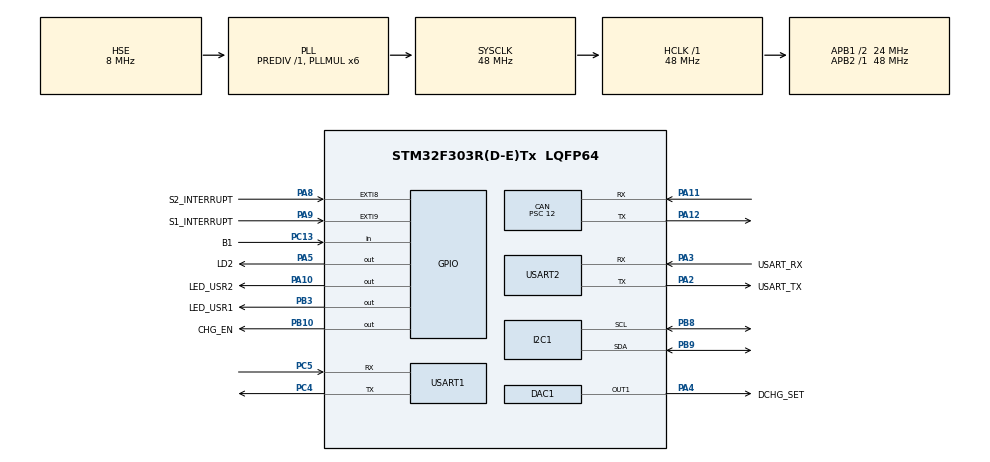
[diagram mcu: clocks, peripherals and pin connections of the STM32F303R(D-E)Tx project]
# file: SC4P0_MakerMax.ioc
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CAN.BS1=CAN_BS1_13TQ
CAN.BS2=CAN_BS2_2TQ
CAN.CalculateTimeQuantum=500.0
CAN.Mode=CAN_MODE_NORMAL
CAN.NART=ENABLE
CAN.Prescaler=12
FREERTOS.MEMORY_ALLOCATION=1
FREERTOS.Tasks01=defaultTask,0,1024,StartDefaultTask,Default,NULL,Static,defaultTaskBuffer,defaultTaskControlBlock
FREERTOS.configMAX_PRIORITIES=7
FREERTOS.configMINIMAL_STACK_SIZE=1024
FREERTOS.configTOTAL_HEAP_SIZE=15360
FREERTOS.configUSE_PREEMPTION=0
I2C1.AddressingMode=I2C_ADDRESSINGMODE_7BIT
Mcu.Family=STM32F3
Mcu.Name=STM32F303R(D-E)Tx
Mcu.Package=LQFP64
NVIC.EXTI9_5_IRQn=true\:5\:0\:false\:false\:true\:true\:true\:true
NVIC.PriorityGroup=NVIC_PRIORITYGROUP_4
NVIC.TIM1_TRG_COM_TIM17_IRQn=true\:5\:0\:false\:false\:true\:true\:true\:true
NVIC.TIM1_UP_TIM16_IRQn=true\:5\:0\:false\:false\:true\:true\:true\:true
NVIC.TIM6_DAC_IRQn=true\:5\:0\:false\:false\:true\:true\:true\:true
NVIC.TIM7_IRQn=true\:5\:0\:false\:false\:true\:true\:true\:true
NVIC.USART1_IRQn=true\:5\:0\:false\:false\:true\:true\:true\:true
NVIC.USB_LP_CAN_RX0_IRQn=true\:5\:0\:false\:false\:true\:true\:true\:true
PA10.GPIO_Label=LED_USR2
PA10.GPIO_ModeDefaultOutputPP=GPIO_MODE_OUTPUT_PP
PA10.GPIO_PuPd=GPIO_NOPULL
PA10.GPIO_Speed=GPIO_SPEED_FREQ_LOW
PA10.PinState=GPIO_PIN_RESET
PA10.Signal=GPIO_Output
PA11.Mode=Master
PA11.Signal=CAN_RX
PA12.Mode=Master
PA12.Signal=CAN_TX
PA13.GPIO_Label=TMS
PA13.Mode=Serial_Wire
PA13.Signal=SYS_JTMS-SWDIO
PA14.GPIO_Label=TCK
PA14.Mode=Serial_Wire
PA14.Signal=SYS_JTCK-SWCLK
PA2.GPIO_Label=USART_TX
PA2.GPIO_Mode=GPIO_MODE_AF_PP
PA2.GPIO_ModeDefaultPP=GPIO_MODE_AF_PP
PA2.GPIO_PuPd=GPIO_NOPULL
PA2.GPIO_Speed=GPIO_SPEED_FREQ_HIGH
PA2.Mode=Asynchronous
PA2.Signal=USART2_TX
PA3.GPIO_Label=USART_RX
PA3.GPIO_Mode=GPIO_MODE_AF_PP
PA3.GPIO_ModeDefaultPP=GPIO_MODE_AF_PP
PA3.GPIO_PuPd=GPIO_NOPULL
PA3.GPIO_Speed=GPIO_SPEED_FREQ_HIGH
PA3.Mode=Asynchronous
PA3.Signal=USART2_RX
PA4.GPIO_Label=DCHG_SET
PA4.GPIO_Mode=GPIO_MODE_ANALOG
PA4.GPIO_PuPd=GPIO_NOPULL
PA4.Signal=COMP_DAC11_group
PA5.GPIO_Label=LD2
PA5.GPIO_Mode=GPIO_MODE_OUTPUT_PP
PA5.GPIO_ModeDefaultOutputPP=GPIO_MODE_OUTPUT_PP
PA5.GPIO_PuPd=GPIO_NOPULL
PA5.GPIO_Speed=GPIO_SPEED_FREQ_LOW
PA5.PinState=GPIO_PIN_RESET
PA5.Signal=GPIO_Output
PA8.GPIO_Label=S2_INTERRUPT
PA8.GPIO_ModeDefaultEXTI=GPIO_MODE_IT_FALLING
PA8.GPIO_PuPd=GPIO_PULLUP
PA8.Signal=GPXTI8
PA9.GPIO_Label=S1_INTERRUPT
PA9.GPIO_ModeDefaultEXTI=GPIO_MODE_IT_FALLING
PA9.GPIO_PuPd=GPIO_PULLUP
PA9.Signal=GPXTI9
PB10.GPIO_Label=CHG_EN
PB10.GPIO_ModeDefaultOutputPP=GPIO_MODE_OUTPUT_PP
PB10.GPIO_PuPd=GPIO_NOPULL
PB10.GPIO_Speed=GPIO_SPEED_FREQ_LOW
PB10.PinState=GPIO_PIN_RESET
PB10.Signal=GPIO_Output
PB3.GPIO_Label=LED_USR1
PB3.GPIO_ModeDefaultOutputPP=GPIO_MODE_OUTPUT_PP
PB3.GPIO_PuPd=GPIO_NOPULL
PB3.GPIO_Speed=GPIO_SPEED_FREQ_LOW
PB3.PinState=GPIO_PIN_RESET
PB3.Signal=GPIO_Output
PB8.GPIO_Mode=GPIO_MODE_AF_OD
PB8.GPIO_PuPdOD=GPIO_NOPULL
PB8.GPIO_Speed=GPIO_SPEED_FREQ_HIGH
PB8.Mode=I2C
PB8.Signal=I2C1_SCL
PB9.GPIO_FM7=__NULL
PB9.GPIO_Mode=GPIO_MODE_AF_OD
PB9.GPIO_PuPdOD=GPIO_NOPULL
PB9.GPIO_Speed=GPIO_SPEED_FREQ_HIGH
PB9.Mode=I2C
PB9.Signal=I2C1_SDA
PC13.GPIO_Label=B1
PC13.Signal=GPIO_Input
PC14-OSC32_IN.Signal=RCC_OSC32_IN
PC15-OSC32_OUT.Signal=RCC_OSC32_OUT
PC4.Mode=Asynchronous
PC4.Signal=USART1_TX
PC5.Mode=Asynchronous
PC5.Signal=USART1_RX
PF0-OSC_IN.Mode=HSE-External-Oscillator
PF0-OSC_IN.Signal=RCC_OSC_IN
PF1-OSC_OUT.Mode=HSE-External-Oscillator
PF1-OSC_OUT.Signal=RCC_OSC_OUT
ProjectManager.HeapSize=0x200
ProjectManager.StackSize=0x400
ProjectManager.TargetToolchain=TrueSTUDIO
RCC.AHBFreq_Value=48000000
RCC.APB1CLKDivider=RCC_HCLK_DIV2
RCC.APB1Freq_Value=24000000
RCC.APB1TimFreq_Value=48000000
RCC.APB2Freq_Value=48000000
RCC.APB2TimFreq_Value=48000000
RCC.CortexFreq_Value=48000000
RCC.HCLKFreq_Value=48000000
RCC.HSE_VALUE=8000000
RCC.HSI_VALUE=8000000
RCC.LSE_VALUE=32768
RCC.PLLM=8
RCC.PLLMUL=RCC_PLL_MUL6
RCC.PLLN=336
RCC.PLLP=RCC_PLLP_DIV4
RCC.PLLQ=7
RCC.PLLSourceVirtual=RCC_PLLSOURCE_HSE
RCC.RCC_PLLsource_Clock_Source_FROM_HSE=RCC_HSE_PREDIV_DIV2
RCC.SYSCLKFreq_VALUE=48000000
RCC.SYSCLKSourceVirtual=RCC_SYSCLKSOURCE_PLLCLK
RCC.USBFreq_Value=48000000
SH.COMP_DAC11_group.0=DAC1_OUT1,DAC_OUT1
TIM16.Period=2500
TIM16.Prescaler=36000
TIM17.Period=2500
TIM17.Prescaler=36000
TIM6.Period=2500
TIM6.Prescaler=36000
TIM7.Period=0
TIM7.Prescaler=0
USART1.VirtualMode-Asynchronous=VM_ASYNC
USART2.VirtualMode-Asynchronous=VM_ASYNC
VP_FREERTOS_VS_CMSIS_V1.Mode=CMSIS_V1
VP_TIM16_VS_ClockSourceINT.Mode=Enable_Timer
VP_TIM17_VS_ClockSourceINT.Mode=Enable_Timer
VP_TIM6_VS_ClockSourceINT.Mode=Enable_Timer
VP_TIM7_VS_ClockSourceINT.Mode=Enable_Timer
board=NUCLEO-F303RE

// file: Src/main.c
/* USER CODE BEGIN Header */
/**
  ******************************************************************************
  * @file           : main.c
  * @brief          : Main program body
  ******************************************************************************
  ** This notice applies to any and all portions of this file
  * that are not between comment pairs USER CODE BEGIN and
  * USER CODE END. Other portions of this file, whether
  * inserted by the user or by software development tools
  * are owned by their respective copyright owners.
  *
  * COPYRIGHT(c) 2019 STMicroelectronics and MakerMax Inc.
  *
  * Redistribution and use in source and binary forms, with or without modification,
  * are permitted provided that the following conditions are met:
  *   1. Redistributions of source code must retain the above copyright notice,
  *      this list of conditions and the following disclaimer.
  *   2. Redistributions in binary form must reproduce the above copyright notice,
  *      this list of conditions and the following disclaimer in the documentation
  *      and/or other materials provided with the distribution.
  *   3. Neither the name of STMicroelectronics nor the names of its contributors
  *      may be used to endorse or promote products derived from this software
  *      without specific prior written permission.
  *
  * THIS SOFTWARE IS PROVIDED BY THE COPYRIGHT HOLDERS AND CONTRIBUTORS "AS IS"
  * AND ANY EXPRESS OR IMPLIED WARRANTIES, INCLUDING, BUT NOT LIMITED TO, THE
  * IMPLIED WARRANTIES OF MERCHANTABILITY AND FITNESS FOR A PARTICULAR PURPOSE ARE
  * DISCLAIMED. IN NO EVENT SHALL THE COPYRIGHT HOLDER OR CONTRIBUTORS BE LIABLE
  * FOR ANY DIRECT, INDIRECT, INCIDENTAL, SPECIAL, EXEMPLARY, OR CONSEQUENTIAL
  * DAMAGES (INCLUDING, BUT NOT LIMITED TO, PROCUREMENT OF SUBSTITUTE GOODS OR
  * SERVICES; LOSS OF USE, DATA, OR PROFITS; OR BUSINESS INTERRUPTION) HOWEVER
  * CAUSED AND ON ANY THEORY OF LIABILITY, WHETHER IN CONTRACT, STRICT LIABILITY,
  * OR TORT (INCLUDING NEGLIGENCE OR OTHERWISE) ARISING IN ANY WAY OUT OF THE USE
  * OF THIS SOFTWARE, EVEN IF ADVISED OF THE POSSIBILITY OF SUCH DAMAGE.
  *
  ******************************************************************************
  */
/* USER CODE END Header */

#include "main.h"
#include "cmsis_os.h"

/* USER CODE BEGIN Includes */
//#include <stdarg.h>
#include <stdio.h>
#include <string.h>
#include "bms.h"
#include "can.h"
#include "modbus_helper.h"

/* USER CODE END Includes */

CAN_HandleTypeDef hcan;

DAC_HandleTypeDef hdac1;

I2C_HandleTypeDef hi2c1;

TIM_HandleTypeDef htim6;
TIM_HandleTypeDef htim7;
TIM_HandleTypeDef htim16;
TIM_HandleTypeDef htim17;

UART_HandleTypeDef huart1;
UART_HandleTypeDef huart2;

osThreadId defaultTaskHandle;
uint32_t defaultTaskBuffer[ 1024 ];
osStaticThreadDef_t defaultTaskControlBlock;

void SystemClock_Config(void);
static void MX_GPIO_Init(void);
static void MX_DAC1_Init(void);
static void MX_I2C1_Init(void);
static void MX_TIM6_Init(void);
static void MX_USART2_UART_Init(void);
static void MX_TIM7_Init(void);
static void MX_TIM16_Init(void);
static void MX_TIM17_Init(void);
static void MX_USART1_UART_Init(void);
static void MX_CAN_Init(void);
void StartDefaultTask(void const * argument);

int main(void)
{

  /* MCU Configuration--------------------------------------------------------*/

  /* Reset of all peripherals, Initializes the Flash interface and the Systick. */
  HAL_Init();

  /* Configure the system clock */
  SystemClock_Config();

  /* Initialize all configured peripherals */
  MX_GPIO_Init();
  MX_DAC1_Init();
  MX_I2C1_Init();
  MX_TIM6_Init();
  MX_USART2_UART_Init();
  MX_TIM7_Init();
  MX_TIM16_Init();
  MX_TIM17_Init();
  MX_USART1_UART_Init();
  MX_CAN_Init();
  /* USER CODE BEGIN 2 */

  /*
   * Initialize TIM7 to run safety loop
   */

  //HAL_TIM_Base_Start_IT(&htim7);
  HAL_TIM_Base_Start_IT(&htim16);

  /*
   * Initialize BMS
   */
  InitBMS();

  /*
   * Initialize CAN
   */
  InitCAN();

  /*
   * Initialize modbus
   */
  enable_modbusrtu();

  /* USER CODE END 2 */

  /* Create the thread(s) */
  /* definition and creation of defaultTask */
  //osThreadStaticDef(defaultTask, StartDefaultTask, osPriorityNormal, 0, 1024, defaultTaskBuffer, &defaultTaskControlBlock);
  //defaultTaskHandle = osThreadCreate(osThread(defaultTask), NULL);

  /* USER CODE BEGIN RTOS_THREADS */
  /* add threads, ... */

  bms_task_init();
  can_task_init();
  modbus_task_init();

  /* USER CODE END RTOS_THREADS */

  /* Start scheduler */
  osKernelStart();

  /* We should never get here as control is now taken by the scheduler */

  /* Infinite loop */
  while (1)
  {

  }
}

void SystemClock_Config(void)
{
  RCC_OscInitTypeDef RCC_OscInitStruct = {0};
  RCC_ClkInitTypeDef RCC_ClkInitStruct = {0};
  RCC_PeriphCLKInitTypeDef PeriphClkInit = {0};

  /** Initializes the CPU, AHB and APB busses clocks
  */
  RCC_OscInitStruct.OscillatorType = RCC_OSCILLATORTYPE_HSI|RCC_OSCILLATORTYPE_HSE;
  RCC_OscInitStruct.HSEState = RCC_HSE_ON;
  RCC_OscInitStruct.HSIState = RCC_HSI_ON;
  RCC_OscInitStruct.HSICalibrationValue = RCC_HSICALIBRATION_DEFAULT;
  RCC_OscInitStruct.PLL.PLLState = RCC_PLL_ON;
  RCC_OscInitStruct.PLL.PLLSource = RCC_PLLSOURCE_HSE;
  RCC_OscInitStruct.PLL.PLLMUL = RCC_PLL_MUL6;
  RCC_OscInitStruct.PLL.PREDIV = RCC_PREDIV_DIV1;
  if (HAL_RCC_OscConfig(&RCC_OscInitStruct) != HAL_OK)
  {
    Error_Handler();
  }
  /** Initializes the CPU, AHB and APB busses clocks
  */
  RCC_ClkInitStruct.ClockType = RCC_CLOCKTYPE_HCLK|RCC_CLOCKTYPE_SYSCLK
                              |RCC_CLOCKTYPE_PCLK1|RCC_CLOCKTYPE_PCLK2;
  RCC_ClkInitStruct.SYSCLKSource = RCC_SYSCLKSOURCE_PLLCLK;
  RCC_ClkInitStruct.AHBCLKDivider = RCC_SYSCLK_DIV1;
  RCC_ClkInitStruct.APB1CLKDivider = RCC_HCLK_DIV2;
  RCC_ClkInitStruct.APB2CLKDivider = RCC_HCLK_DIV1;

  if (HAL_RCC_ClockConfig(&RCC_ClkInitStruct, FLASH_LATENCY_1) != HAL_OK)
  {
    Error_Handler();
  }
  PeriphClkInit.PeriphClockSelection = RCC_PERIPHCLK_USART1|RCC_PERIPHCLK_USART2
                              |RCC_PERIPHCLK_I2C1|RCC_PERIPHCLK_TIM16
                              |RCC_PERIPHCLK_TIM17;
  PeriphClkInit.Usart1ClockSelection = RCC_USART1CLKSOURCE_PCLK2;
  PeriphClkInit.Usart2ClockSelection = RCC_USART2CLKSOURCE_PCLK1;
  PeriphClkInit.I2c1ClockSelection = RCC_I2C1CLKSOURCE_HSI;
  PeriphClkInit.Tim16ClockSelection = RCC_TIM16CLK_HCLK;
  PeriphClkInit.Tim17ClockSelection = RCC_TIM17CLK_HCLK;
  if (HAL_RCCEx_PeriphCLKConfig(&PeriphClkInit) != HAL_OK)
  {
    Error_Handler();
  }
}

static void MX_CAN_Init(void)
{

  hcan.Instance = CAN;
  hcan.Init.Prescaler = 12;
  hcan.Init.Mode = CAN_MODE_NORMAL;
  hcan.Init.SyncJumpWidth = CAN_SJW_1TQ;
  hcan.Init.TimeSeg1 = CAN_BS1_13TQ;
  hcan.Init.TimeSeg2 = CAN_BS2_2TQ;
  hcan.Init.TimeTriggeredMode = DISABLE;
  hcan.Init.AutoBusOff = DISABLE;
  hcan.Init.AutoWakeUp = DISABLE;
  hcan.Init.AutoRetransmission = ENABLE;
  hcan.Init.ReceiveFifoLocked = DISABLE;
  hcan.Init.TransmitFifoPriority = DISABLE;
  if (HAL_CAN_Init(&hcan) != HAL_OK)
  {
    Error_Handler();
  }

}

static void MX_DAC1_Init(void)
{

  DAC_ChannelConfTypeDef sConfig = {0};

  /** DAC Initialization
  */
  hdac1.Instance = DAC1;
  if (HAL_DAC_Init(&hdac1) != HAL_OK)
  {
    Error_Handler();
  }
  /** DAC channel OUT1 config
  */
  sConfig.DAC_Trigger = DAC_TRIGGER_NONE;
  sConfig.DAC_OutputBuffer = DAC_OUTPUTBUFFER_ENABLE;
  if (HAL_DAC_ConfigChannel(&hdac1, &sConfig, DAC_CHANNEL_1) != HAL_OK)
  {
    Error_Handler();
  }

}

static void MX_I2C1_Init(void)
{

  hi2c1.Instance = I2C1;
  hi2c1.Init.Timing = 0x2000090E;
  hi2c1.Init.OwnAddress1 = 0;
  hi2c1.Init.AddressingMode = I2C_ADDRESSINGMODE_7BIT;
  hi2c1.Init.DualAddressMode = I2C_DUALADDRESS_DISABLE;
  hi2c1.Init.OwnAddress2 = 0;
  hi2c1.Init.OwnAddress2Masks = I2C_OA2_NOMASK;
  hi2c1.Init.GeneralCallMode = I2C_GENERALCALL_DISABLE;
  hi2c1.Init.NoStretchMode = I2C_NOSTRETCH_DISABLE;
  if (HAL_I2C_Init(&hi2c1) != HAL_OK)
  {
    Error_Handler();
  }
  /** Configure Analogue filter
  */
  if (HAL_I2CEx_ConfigAnalogFilter(&hi2c1, I2C_ANALOGFILTER_ENABLE) != HAL_OK)
  {
    Error_Handler();
  }
  /** Configure Digital filter
  */
  if (HAL_I2CEx_ConfigDigitalFilter(&hi2c1, 0) != HAL_OK)
  {
    Error_Handler();
  }

}

static void MX_TIM6_Init(void)
{

  TIM_MasterConfigTypeDef sMasterConfig = {0};

  htim6.Instance = TIM6;
  htim6.Init.Prescaler = 36000;
  htim6.Init.CounterMode = TIM_COUNTERMODE_UP;
  htim6.Init.Period = 2500;
  htim6.Init.AutoReloadPreload = TIM_AUTORELOAD_PRELOAD_DISABLE;
  if (HAL_TIM_Base_Init(&htim6) != HAL_OK)
  {
    Error_Handler();
  }
  sMasterConfig.MasterOutputTrigger = TIM_TRGO_RESET;
  sMasterConfig.MasterSlaveMode = TIM_MASTERSLAVEMODE_DISABLE;
  if (HAL_TIMEx_MasterConfigSynchronization(&htim6, &sMasterConfig) != HAL_OK)
  {
    Error_Handler();
  }

}

static void MX_TIM7_Init(void)
{

  TIM_MasterConfigTypeDef sMasterConfig = {0};

  htim7.Instance = TIM7;
  htim7.Init.Prescaler = 0;
  htim7.Init.CounterMode = TIM_COUNTERMODE_UP;
  htim7.Init.Period = 0;
  htim7.Init.AutoReloadPreload = TIM_AUTORELOAD_PRELOAD_DISABLE;
  if (HAL_TIM_Base_Init(&htim7) != HAL_OK)
  {
    Error_Handler();
  }
  sMasterConfig.MasterOutputTrigger = TIM_TRGO_RESET;
  sMasterConfig.MasterSlaveMode = TIM_MASTERSLAVEMODE_DISABLE;
  if (HAL_TIMEx_MasterConfigSynchronization(&htim7, &sMasterConfig) != HAL_OK)
  {
    Error_Handler();
  }

}

static void MX_TIM16_Init(void)
{

  htim16.Instance = TIM16;
  htim16.Init.Prescaler = 36000;
  htim16.Init.CounterMode = TIM_COUNTERMODE_UP;
  htim16.Init.Period = 2500;
  htim16.Init.ClockDivision = TIM_CLOCKDIVISION_DIV1;
  htim16.Init.RepetitionCounter = 0;
  htim16.Init.AutoReloadPreload = TIM_AUTORELOAD_PRELOAD_DISABLE;
  if (HAL_TIM_Base_Init(&htim16) != HAL_OK)
  {
    Error_Handler();
  }

}

static void MX_TIM17_Init(void)
{

  htim17.Instance = TIM17;
  htim17.Init.Prescaler = 36000;
  htim17.Init.CounterMode = TIM_COUNTERMODE_UP;
  htim17.Init.Period = 2500;
  htim17.Init.ClockDivision = TIM_CLOCKDIVISION_DIV1;
  htim17.Init.RepetitionCounter = 0;
  htim17.Init.AutoReloadPreload = TIM_AUTORELOAD_PRELOAD_DISABLE;
  if (HAL_TIM_Base_Init(&htim17) != HAL_OK)
  {
    Error_Handler();
  }

}

static void MX_USART1_UART_Init(void)
{

  huart1.Instance = USART1;
  huart1.Init.BaudRate = 38400;
  huart1.Init.WordLength = UART_WORDLENGTH_8B;
  huart1.Init.StopBits = UART_STOPBITS_1;
  huart1.Init.Parity = UART_PARITY_NONE;
  huart1.Init.Mode = UART_MODE_TX_RX;
  huart1.Init.HwFlowCtl = UART_HWCONTROL_NONE;
  huart1.Init.OverSampling = UART_OVERSAMPLING_16;
  huart1.Init.OneBitSampling = UART_ONE_BIT_SAMPLE_DISABLE;
  huart1.AdvancedInit.AdvFeatureInit = UART_ADVFEATURE_NO_INIT;
  if (HAL_UART_Init(&huart1) != HAL_OK)
  {
    Error_Handler();
  }
  /* USER CODE BEGIN USART1_Init 2 */

  //HAL_UART_Transmit(&huart1, (uint8_t *)'I' , 1, 10);

  /* USER CODE END USART1_Init 2 */

}

static void MX_USART2_UART_Init(void)
{

  huart2.Instance = USART2;
  huart2.Init.BaudRate = 38400;
  huart2.Init.WordLength = UART_WORDLENGTH_8B;
  huart2.Init.StopBits = UART_STOPBITS_1;
  huart2.Init.Parity = UART_PARITY_NONE;
  huart2.Init.Mode = UART_MODE_TX_RX;
  huart2.Init.HwFlowCtl = UART_HWCONTROL_NONE;
  huart2.Init.OverSampling = UART_OVERSAMPLING_16;
  huart2.Init.OneBitSampling = UART_ONE_BIT_SAMPLE_DISABLE;
  huart2.AdvancedInit.AdvFeatureInit = UART_ADVFEATURE_NO_INIT;
  if (HAL_UART_Init(&huart2) != HAL_OK)
  {
    Error_Handler();
  }

}

static void MX_GPIO_Init(void)
{
  GPIO_InitTypeDef GPIO_InitStruct = {0};

  /* GPIO Ports Clock Enable */
  __HAL_RCC_GPIOC_CLK_ENABLE();
  __HAL_RCC_GPIOF_CLK_ENABLE();
  __HAL_RCC_GPIOA_CLK_ENABLE();
  __HAL_RCC_GPIOB_CLK_ENABLE();

  /*Configure GPIO pin Output Level */
  HAL_GPIO_WritePin(GPIOA, LD2_Pin|LED_USR2_Pin, GPIO_PIN_RESET);

  /*Configure GPIO pin Output Level */
  HAL_GPIO_WritePin(GPIOB, CHG_EN_Pin|LED_USR1_Pin, GPIO_PIN_RESET);

  /*Configure GPIO pin : B1_Pin */
  GPIO_InitStruct.Pin = B1_Pin;
  GPIO_InitStruct.Mode = GPIO_MODE_INPUT;
  GPIO_InitStruct.Pull = GPIO_NOPULL;
  HAL_GPIO_Init(B1_GPIO_Port, &GPIO_InitStruct);

  /*Configure GPIO pins : LD2_Pin LED_USR2_Pin */
  GPIO_InitStruct.Pin = LD2_Pin|LED_USR2_Pin;
  GPIO_InitStruct.Mode = GPIO_MODE_OUTPUT_PP;
  GPIO_InitStruct.Pull = GPIO_NOPULL;
  GPIO_InitStruct.Speed = GPIO_SPEED_FREQ_LOW;
  HAL_GPIO_Init(GPIOA, &GPIO_InitStruct);

  /*Configure GPIO pins : CHG_EN_Pin LED_USR1_Pin */
  GPIO_InitStruct.Pin = CHG_EN_Pin|LED_USR1_Pin;
  GPIO_InitStruct.Mode = GPIO_MODE_OUTPUT_PP;
  GPIO_InitStruct.Pull = GPIO_NOPULL;
  GPIO_InitStruct.Speed = GPIO_SPEED_FREQ_LOW;
  HAL_GPIO_Init(GPIOB, &GPIO_InitStruct);

  /*Configure GPIO pins : S2_INTERRUPT_Pin S1_INTERRUPT_Pin */
  GPIO_InitStruct.Pin = S2_INTERRUPT_Pin|S1_INTERRUPT_Pin;
  GPIO_InitStruct.Mode = GPIO_MODE_IT_FALLING;
  GPIO_InitStruct.Pull = GPIO_PULLUP;
  HAL_GPIO_Init(GPIOA, &GPIO_InitStruct);

  /* EXTI interrupt init*/
  HAL_NVIC_SetPriority(EXTI9_5_IRQn, 5, 0);
  HAL_NVIC_EnableIRQ(EXTI9_5_IRQn);

}

void StartDefaultTask(void const * argument)
{
}

void Error_Handler(void)
{
}

/************************ (C) COPYRIGHT STMicroelectronics *****END OF FILE****/
